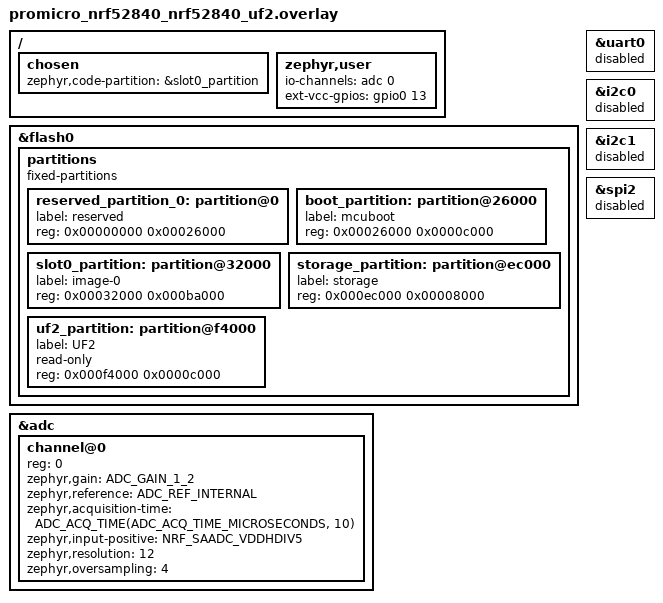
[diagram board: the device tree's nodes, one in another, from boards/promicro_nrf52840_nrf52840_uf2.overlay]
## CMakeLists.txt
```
#
# Copyright (c) 2025 Nordic Semiconductor ASA
#
# SPDX-License-Identifier: LicenseRef-Nordic-5-Clause
#

cmake_minimum_required(VERSION 3.20.0)

find_package(Zephyr REQUIRED HINTS $ENV{ZEPHYR_BASE})
project(beacon)

target_sources(app PRIVATE
    src/main.c
    src/bmt_auth.c
    src/bmt_beacon.c
    src/bmt_battery.c
)
```

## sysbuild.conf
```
# [SECURITY] MCUboot — tuong duong Secure Boot V2 ben ESP32 Tag.
# Single-slot mode: MCUboot chi verify chu ky + boot slot0_partition, chua
# ho tro OTA qua BLE (update = re-flash UF2 toan bo qua Adafruit bootloader
# co san, xem boards/xiao_ble_nrf52840.overlay de biet ly do layout nay).
SB_CONFIG_BOOTLOADER_MCUBOOT=y
SB_CONFIG_MCUBOOT_MODE_SINGLE_APP=y
SB_CONFIG_BOOT_SIGNATURE_TYPE_ECDSA_P256=y
SB_CONFIG_BOOT_SIGNATURE_KEY_FILE="../../mcuboot_keys/bmt_tag_ecdsa_p256.pem"
```

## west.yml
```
# Freestanding Zephyr application manifest. Lets `west init -l .` set up
# a workspace that pulls in upstream Zephyr next to this app, without
# requiring the whole nRF Connect SDK.
manifest:
  self:
    path: apps/Beacon_ProMicroNrf52840
  remotes:
    - name: zephyrproject
      url-base: https://github.com/zephyrproject-rtos
  projects:
    - name: zephyr
      remote: zephyrproject
      revision: v4.0.0
      import:
        name-allowlist:
          - hal_nordic
          - mcuboot
          - cmsis
          - segger
          - tinycrypt
```

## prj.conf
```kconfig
CONFIG_BT=y
CONFIG_BT_DEVICE_NAME="Test beacon"

# =====================================================================
# [POWER] Disable USB + CONSOLE + LOG — the largest single saving (~0.7 mA)
# =====================================================================
#
# The board uses USB CDC-ACM as its console (no dedicated UART for debug),
# so just having CONFIG_CONSOLE=y drags in the full USB device stack and
# keeps it running forever: CONFIG_USB_DEVICE_STACK_NEXT + CONFIG_UDC_NRF.
# Because CONFIG_PM_DEVICE is not enabled, nothing suspends them -> current
# is drawn continuously EVEN AFTER the USB cable is unplugged.
#
# Measured on this board (running from battery, USB unplugged, DT-9205A on
# the 200 mA range):
#   Full firmware (with USB / log)         1.7 mA
#   Empty firmware (no USB / log / BLE)    1.0 mA   <- the 0.7 mA diff is USB
#   Empty firmware + P0.13 LOW             0.9 mA   <- hardware floor, nothing to do
#
# DEBUG NOTE: turning this off means NO COM port and NO log. When you need
# logs, build with debug.conf to bring them back (see README, Build).
#
# Trying just CONFIG_LOG=n does NOT help — it only stops printing; the USB
# stack still initialises and runs. You must disable the console for the
# USB stack to actually be dropped from the build.
# THIS is the right switch (one line, instead of picking off each symbol).
# See zephyr/boards/common/usb/Kconfig.cdc_acm_serial.defconfig — the whole
#     if BOARD_SERIAL_BACKEND_CDC_ACM
#         config SERIAL                          default y
#         config CONSOLE                         default y
#         config USB_DEVICE_STACK_NEXT           default y if !MCUBOOT
#         config CDC_ACM_SERIAL_INITIALIZE_AT_BOOT  default y if !MCUBOOT
# block hangs off this switch, so disabling it drops the whole cluster.
#
# (Tried the piecemeal CONFIG_CONSOLE / UART_CONSOLE / SERIAL / LOG=n approach
#  first — did NOT work: .config still had USB_DEVICE_STACK_NEXT=y and
#  UDC_NRF=y, plus the build failed with "'__device_dts_ord_106' undeclared"
#  because cdc_acm_serial.c was still being compiled while the usbd node was
#  disabled in devicetree.)
CONFIG_BOARD_SERIAL_BACKEND_CDC_ACM=n
CONFIG_LOG=n

# [POWER] Turn off the soft switch that feeds power to the external VCC pin
# (P0.13) — saves ~0.1 mA. Needs the GPIO driver. See src/main.c and the
# overlay for the schematic detail.
CONFIG_GPIO=y

# PSA Crypto (HMAC-SHA256) — needed by bmt_auth for epoch key rotation.
CONFIG_PSA_CRYPTO=y
CONFIG_PSA_WANT_ALG_HMAC=y
CONFIG_PSA_WANT_ALG_SHA_256=y
CONFIG_PSA_WANT_KEY_TYPE_HMAC=y

# [POWER] Drop the radio TX power from the default 0 dBm to -4 dBm (matches
# the XIAO variant).
CONFIG_BT_CTLR_TX_PWR_MINUS_4=y

# [POWER] Read battery via the internal VDDHDIV5 — see bmt_battery.c and
# the overlay.
CONFIG_ADC=y

# =====================================================================
# [POWER] KEY DIFFERENCE VS THE XIAO VARIANT — DC/DC regulator
# =====================================================================
#
# The nRF52840 has TWO separate DC/DC regulators for two power architectures:
#
#  - REG1 ("normal voltage"): used when VDD is fed by an external LDO that
#    has already stepped the rail down. This is the XIAO case (battery ->
#    BQ25101 -> LDO SGM2040 3.3 V). The XIAO board devicetree ships both
#    regulators enabled:
#         &reg0 { status = "okay"; };
#         &reg1 { regulator-initial-mode = <NRF5X_REG_MODE_DCDC>; };
#    plus the L3 10 uH inductor between DCC / DEC4.
#
#  - REG0 ("high voltage"): used when the battery wires directly into VDDH
#    — the ProMicro / nice!nano v2 architecture.
#
# The ProMicro board in Zephyr does NOT configure reg0 / reg1 at all, so both
# stay at their defaults (REG1 in LDO mode, not DCDC).
#
# NOTE: the two legacy Kconfig symbols (CONFIG_SOC_DCDC_NRF52X / _HV) are
# DEPRECATED in this Zephyr version — DCDC must be enabled through
# DEVICETREE as shown above, not through prj.conf. (The
# CONFIG_BOARD_ENABLE_DCDC_HV symbol some ZMK guides mention is a ZMK-only
# thing and does not exist in upstream Zephyr.)
#
# NOT enabled in the initial version — DELIBERATE:
#   1) Cannot confirm this clone board has the inductor DCDC needs.
#   2) Real-world data from the ZMK community (issue zmkfirmware/zmk#2990)
#      shows enabling DC/DC HV mode on this class of board can INCREASE
#      current:
#         - Official nice!nano: +0.12-0.48 mA standby (up 20-25%)
#         - Clone boards: +1.30-1.32 mA (!!)
#      Suspicion: clones drop the inductor, so the switcher misbehaves
#      and draws more than the LDO would.
#
# => PLAN: measure current at the default first, then try enabling DCDC via
#    devicetree and remeasure. Only keep it if the numbers actually improve.

# =====================================================================
# [POWER] [TODO — not done, deliberate] Turn off unused peripherals
# =====================================================================
# The ProMicro board enables more peripherals than XIAO: i2c0, i2c1, pwm0,
# spi2, uart0 (see promicro_nrf52840_nrf52840_common.dts). This beacon app
# uses none of them, so disabling in principle would save a bit more.
#
# NOT done in the initial version: first want a WORKING image plus baseline
# current measurement, then disable one at a time AND remeasure to confirm
# each step. (Lesson from the XIAO variant: disabling SPI2 was thought to
# have hung the board, wasted hours debugging — the real culprit was
# flashing an unsigned app image. Since then, verify one config change at
# a time; don't change many things at once.)
#
# WATCH OUT: pwm0 is referenced by the "pwmleds" node (red_pwm_led);
# disabling pwm0 without handling that node will break the build.
```

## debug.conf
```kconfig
# =====================================================================
# DEBUG BUILD — re-enable console / log over USB CDC-ACM
# =====================================================================
#
# prj.conf (production) DISABLES USB + console + log because they draw
# ~0.7 mA continuously even after the USB cable is unplugged — see the
# full explanation in prj.conf.
#
# This file re-enables them so you can read logs for debugging. DO NOT
# USE FOR CURRENT MEASUREMENT: the reading will be ~0.7 mA higher than
# the real firmware.
#
# Build command:
#   west build -b promicro_nrf52840/nrf52840/uf2 -d build_debug . --pristine \
#       -- "-DBeacon_ProMicroNrf52840_EXTRA_CONF_FILE=debug.conf"
#
# (The "Beacon_ProMicroNrf52840_" prefix is required — this is a
#  sysbuild multi-image build; without the prefix CMake configure will
#  fail.)

# Re-enable the switch that prj.conf turned off. This drags in the
# whole cluster: SERIAL, CONSOLE, UART_CONSOLE, USB_DEVICE_STACK_NEXT,
# CDC_ACM_SERIAL_INITIALIZE_AT_BOOT (see prj.conf for the detail).
#
# NOTE: setting only CONFIG_CONSOLE=y / SERIAL=y without this line is
# USELESS — the console comes up but there is no UART device to send
# output to, so no COM port appears. (Been caught by this once.)
CONFIG_BOARD_SERIAL_BACKEND_CDC_ACM=y
CONFIG_LOG=y

# Bump the USB buffer pool to avoid "udc: Failed to allocate net_buf N"
# when USB control transactions and CDC-ACM log traffic overlap (after
# SUSPEND / RESUME).
CONFIG_UDC_BUF_POOL_SIZE=4096
CONFIG_UDC_BUF_COUNT=32
```

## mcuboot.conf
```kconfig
# [SECURITY] MCUboot tren XIAO nRF52840 dung USB CDC-ACM lam console mac dinh
# (board khong co UART debug rieng), nhung MCUboot KHONG bat USB stack (bootloader
# toi gian, khong can). Ket qua: console driver bi thieu link -> "undefined
# reference to __device_dts_ord_N". MCUboot khong can in log gi ca (chi verify
# chu ky + nhay sang slot0_partition) nen tat han console la cach don gian nhat,
# dong thoi giam attack surface (khong lo thong tin version/debug qua serial).
CONFIG_UART_CONSOLE=n
CONFIG_CONSOLE=n
```

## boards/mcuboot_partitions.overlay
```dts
/*
 * [SECURITY] Partition copy of promicro_nrf52840_nrf52840_uf2.overlay,
 * dedicated to MCUboot's own build (not the "beacon" app).
 *
 * WHY A SEPARATE FILE: Zephyr auto-applies boards/<board>.overlay only
 * to the main app. MCUboot is a COMPLETELY SEPARATE Zephyr app that
 * sysbuild builds in its own directory, so the overlay must be passed
 * explicitly via mcuboot_EXTRA_DTC_OVERLAY_FILE (see
 * sysbuild/CMakeLists.txt).
 *
 * DO NOT share a file with the app: "chosen { zephyr,code-partition }"
 * must DIFFER between the two — MCUboot must link into boot_partition
 * (0x26000) while the app must link into slot0_partition (0x32000).
 * Sharing would make MCUboot link into slot0 and overwrite the app
 * itself.
 *
 * (Note the 0x26000 base — DIFFERENT from XIAO at 0x27000. See the
 * full explanation in promicro_nrf52840_nrf52840_uf2.overlay.)
 *
 * This file ONLY declares partitions; no ADC / zephyr,user node —
 * MCUboot does not read the battery, adding one would only bloat the
 * bootloader.
 */

/delete-node/ &reserved_partition_0;
/delete-node/ &code_partition;
/delete-node/ &storage_partition;
/delete-node/ &boot_partition;

/ {
	chosen {
		zephyr,code-partition = &boot_partition;
	};
};

&flash0 {
	partitions {
		compatible = "fixed-partitions";
		#address-cells = <1>;
		#size-cells = <1>;

		reserved_partition_0: partition@0 {
			label = "reserved";
			reg = <0x00000000 0x00026000>;
		};

		boot_partition: partition@26000 {
			label = "mcuboot";
			reg = <0x00026000 0x0000c000>;
		};

		slot0_partition: partition@32000 {
			label = "image-0";
			reg = <0x00032000 0x000ba000>;
		};

		storage_partition: partition@ec000 {
			label = "storage";
			reg = <0x000ec000 0x00008000>;
		};

		uf2_partition: partition@f4000 {
			label = "UF2";
			read-only;
			reg = <0x000f4000 0x0000c000>;
		};
	};
};
```

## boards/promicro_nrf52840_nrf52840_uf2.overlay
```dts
/*
 * [SECURITY + POWER] MCUboot partition layout + battery-read setup —
 * Tag ProMicro nRF52840 (nice!nano v2-compatible, e.g. "Nologo
 * ProMicro nRF52840").
 *
 * ===== KEY DIFFERENCES VS THE XIAO VARIANT =====
 *
 * 1) DIFFERENT APP BASE ADDRESS (0x26000 vs 0x27000):
 *    ProMicro uses the Adafruit UF2 bootloader built for SoftDevice
 *    s140 *v6* (zephyr: nrf52840_partition_uf2_sdv6.dtsi), so the
 *    bootloader jumps to 0x26000. XIAO uses s140 *v7* -> jumps to
 *    0x27000. Put MCUboot at the wrong address and the board never
 *    boots the app.
 *
 * 2) BATTERY READ WITHOUT AN EXTERNAL DIVIDER:
 *    XIAO: battery -> BQ25101 -> external LDO; read via a 1M/510k
 *    divider brought out to P0.31 (AIN7), P0.14 must be driven LOW
 *    to close the measurement path.
 *    ProMicro / nice!nano v2: battery wires DIRECTLY into VDDH, no
 *    external divider — read the voltage via the SAADC's internal
 *    VDDHDIV5 input (= VDDH / 5). No enable pin required, and none
 *    of the Seeed over-voltage warnings for P0.14 apply.
 *
 * Layout (similar to XIAO but shifted down by 0x1000):
 *   0x00000 - 0x26000  reserved         (old SoftDevice region, unused)
 *   0x26000 - 0x32000  boot_partition   (MCUboot, 48 KB)
 *   0x32000 - 0xEC000  slot0_partition  (app, ~744 KB — single-slot)
 *   0xEC000 - 0xF4000  storage_partition (32 KB)
 *   0xF4000 - 0x100000 uf2_partition    (Adafruit bootloader — UNTOUCHED)
 */

/delete-node/ &reserved_partition_0;
/delete-node/ &code_partition;
/delete-node/ &storage_partition;
/delete-node/ &boot_partition;

/ {
	chosen {
		zephyr,code-partition = &slot0_partition;
	};

	/* [POWER] Battery read via the internal VDDHDIV5 (VDDH / 5) —
	 * see the top of file. No external io-channel to declare.
	 *
	 * [POWER] ext-vcc-gpios = SOFT SWITCH that gates the external
	 * VCC pin (P0.13). This board (standard nice!nano v2) has a
	 * MOSFET between the regulator and the external 3.3 V VCC pin,
	 * controlled by P0.13:
	 *     P0.13 HIGH -> VCC ON  |  P0.13 LOW -> VCC OFF
	 * (nice!nano v1 was inverted — v2 and this clone are
	 * active-high.)
	 *
	 * The Zephyr promicro_nrf52840 board definition does NOT
	 * declare this pin, so it stays in the reset state
	 * (input / disconnected) -> the switch defaults to "on" -> the
	 * external VCC rail is always powered, even when the app uses
	 * nothing. Per the SuperMini board's own datasheet, default
	 * standby is ~1000 uA (1 mA); turning this switch off brings
	 * it down to ~150 uA.
	 *
	 * => Matches what we saw: current measured 1.8-1.9 mA and
	 *    would NOT budge no matter what we changed (log off, USB
	 *    buffer resized, uart0 / i2c0 / i2c1 / spi2 disabled) —
	 *    because the leak was on external hardware, not something
	 *    firmware could touch.
	 *
	 * The beacon app powers no external device -> shut it off
	 * completely to save current.
	 */
	zephyr,user {
		io-channels = <&adc 0>;
		ext-vcc-gpios = <&gpio0 13 GPIO_ACTIVE_HIGH>;
	};
};

&flash0 {
	partitions {
		compatible = "fixed-partitions";
		#address-cells = <1>;
		#size-cells = <1>;

		reserved_partition_0: partition@0 {
			label = "reserved";
			reg = <0x00000000 0x00026000>;
		};

		boot_partition: partition@26000 {
			label = "mcuboot";
			reg = <0x00026000 0x0000c000>;
		};

		slot0_partition: partition@32000 {
			label = "image-0";
			reg = <0x00032000 0x000ba000>;
		};

		storage_partition: partition@ec000 {
			label = "storage";
			reg = <0x000ec000 0x00008000>;
		};

		uf2_partition: partition@f4000 {
			label = "UF2";
			read-only;
			reg = <0x000f4000 0x0000c000>;
		};
	};
};

/* [POWER] USB NOTE — do NOT disable here; disable via Kconfig.
 *
 * The board includes <boards/common/usb/cdc_acm_serial.dtsi>, which
 * creates board_cdc_acm_uart under &zephyr_udc0 and points chosen
 * zephyr,console at it. The USB stack draws ~0.8 mA continuously
 * (nearly half of the total), so it must be dropped in the production
 * build — but drop it with **CONFIG_BOARD_SERIAL_BACKEND_CDC_ACM=n**
 * in prj.conf, NOT by disabling the usbd node here.
 *
 * Reason: overlays under boards/ apply to EVERY build. Disabling the
 * usbd node here would break the debug.conf build (re-enables console
 * to read logs) — CONFIG_CONSOLE=y with no UART device to output to
 * leaves you with no COM port. Been caught by this before. Controlling
 * it through Kconfig lets each build enable / disable independently.
 */

/* [POWER TEST] Disable uart0 / i2c0 / i2c1 / spi2 — the board enables
 * these four peripherals with real pinctrl assignments, but the app
 * never touches them, so they may be FLOATING. Suspected as the
 * source of the stubborn ~1.9 mA that would not drop even after
 * disabling logs and resizing the USB buffer.
 * >> ACTUAL MEASUREMENT: no meaningful change (1.9 -> 1.8 mA, within
 *    meter noise). So this is NOT the culprit. Kept the change anyway
 *    because disabling unused peripherals is the right thing to do
 *    and causes no harm.
 * The console still runs over its own USB CDC-ACM path
 * (zephyr_udc0), independent of this physical uart0, so no logs are
 * lost. pwm0 is left alone because it is used by "red_pwm_led" (a
 * status LED). */
&uart0 {
	status = "disabled";
};

&i2c0 {
	status = "disabled";
};

&i2c1 {
	status = "disabled";
};

&spi2 {
	status = "disabled";
};

&adc {
	#address-cells = <1>;
	#size-cells = <0>;
	status = "okay";

	/* Channel 0 maps to the SAADC's internal VDDHDIV5 = VDDH / 5
	 * (no GPIO — the LiPo cell wires straight into VDDH on this
	 * board).
	 *
	 * Gain 1/2 + internal 0.6 V reference -> ADC input range =
	 * 0.6 * 2 = 1.2 V. A LiPo cell at 3.0-4.2 V gives VDDHDIV5
	 * 0.60-0.84 V: fits comfortably in the range with good
	 * resolution (~70% of full-scale at a full cell). Under USB,
	 * VDDH may climb to ~5.5 V -> 1.1 V, still under 1.2 V so no
	 * saturation. (Gain 1/6, as XIAO uses, would waste ~3/4 of
	 * the range here.)
	 *
	 * The source is a low-impedance internal divider, so it does
	 * NOT need the 40 us acquisition time the XIAO variant uses
	 * (which must compensate for the ~342k of the external
	 * divider). The default 10 us is plenty. */
	channel@0 {
		reg = <0>;
		zephyr,gain = "ADC_GAIN_1_2";
		zephyr,reference = "ADC_REF_INTERNAL";
		zephyr,acquisition-time = <ADC_ACQ_TIME(ADC_ACQ_TIME_MICROSECONDS, 10)>;
		zephyr,input-positive = <NRF_SAADC_VDDHDIV5>;
		zephyr,resolution = <12>;
		zephyr,oversampling = <4>;
	};
};
```

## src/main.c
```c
#include <zephyr/kernel.h>
#include <zephyr/sys/printk.h>
#include <zephyr/logging/log.h>

#include <zephyr/bluetooth/bluetooth.h>
#include <zephyr/drivers/gpio.h>

#include "bmt_auth.h"
#include "bmt_beacon.h"
#include "bmt_battery.h"

LOG_MODULE_REGISTER(bmt_main, LOG_LEVEL_INF);

/* [POWER] Soft switch that cuts power to the external VCC pin
 * (P0.13) — full explanation in
 * boards/promicro_nrf52840_nrf52840_uf2.overlay.
 * Summary: the 3.3 V branch routed to the external pin is powered
 * by default (Zephyr does not declare a control pin, so it stays
 * in its reset state), wasting ~1 mA even when the app powers
 * nothing external. */
static const struct gpio_dt_spec ext_vcc =
    GPIO_DT_SPEC_GET(DT_PATH(zephyr_user), ext_vcc_gpios);

static void ext_vcc_off(void)
{
	if (!gpio_is_ready_dt(&ext_vcc))
	{
		LOG_ERR("ext-vcc GPIO not ready");
		return;
	}

	/* INACTIVE + active-high = drive LOW = MOSFET off.
	 * Safe for the MCU: this MOSFET only sits on the external VCC
	 * rail; the nRF52840 itself is powered separately via VDDH. */
	int err = gpio_pin_configure_dt(&ext_vcc, GPIO_OUTPUT_INACTIVE);
	if (err)
	{
		LOG_ERR("Failed to turn off external VCC (err %d)", err);
		return;
	}
	LOG_INF("External VCC pin (P0.13) turned off");
}

static void bt_ready(int err)
{
	if (err)
	{
		LOG_ERR("Bluetooth init failed (err %d)", err);
		return;
	}
	LOG_INF("Bluetooth initialized");

	/* MUST be called before bmt_beacon_start() — the beacon needs
	 * the HMAC key ready so it can compute mac16 for the very
	 * first ADV. */
	bmt_auth_init();

	err = bmt_beacon_start();
	if (err)
	{
		LOG_ERR("bmt_beacon_start failed (err %d)", err);
		return;
	}
	LOG_INF("BMT Tag beacon started");
}

int main(void)
{
	printk("=== BMT Tag (nRF52840) starting ===\n");

	/* As EARLY as possible — every millisecond of delay lets current
	 * waste on the external VCC rail. */
	ext_vcc_off();

	/* Battery reading has nothing to do with BLE, start it in
	 * parallel with bt_enable. */
	int batt_err = bmt_battery_init();
	if (batt_err)
	{
		LOG_ERR("bmt_battery_init failed (err %d)", batt_err);
	}

	int err = bt_enable(bt_ready);
	if (err)
	{
		LOG_ERR("bt_enable failed (err %d)", err);
	}
	return 0;
}
```

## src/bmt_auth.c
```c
#include "bmt_auth.h"

#include <inttypes.h>

#include <zephyr/kernel.h>
#include <zephyr/logging/log.h>
#include "psa/crypto.h"

LOG_MODULE_REGISTER(bmt_auth, LOG_LEVEL_INF);

/* [SECURITY] Master key — NOT used directly to sign the payload. It
 * derives a separate key per epoch (rotated over time, TOTP-style,
 * receiver-less: Tag has no mesh / WiFi, so it cannot receive a
 * pushed rotation like the OTA-beacon key does on Scanner). If this
 * key is stolen from flash, the attacker still has to recompute the
 * current epoch key — they cannot "replay a single static key
 * forever".
 * MUST match BMT_TAG_MASTER_KEY on the ESP32 Tag byte-for-byte. */
static const uint8_t BMT_TAG_MASTER_KEY[16] = {
    0x2C, 0x5C, 0xBE, 0x42, 0x87, 0xAE, 0x95, 0x4A,
    0xDE, 0xEE, 0x0C, 0x6C, 0x8B, 0x74, 0x9C, 0x45};

/* Epoch tick = 1 h. Tag has no RTC / WiFi, so the epoch is a LOCAL
 * counter measured from boot (k_uptime_get(), not wall-clock) —
 * resets to 0 on every power loss (CR2032 swap). Scanner deals with
 * the drift via windowed resync. MUST match the value on the
 * Scanner (ESP32). */
#define BMT_EPOCH_TICK_SEC 3600

static psa_key_id_t s_master_key_id = 0;
static psa_key_id_t s_epoch_key_id = 0;
static uint16_t s_cached_epoch = 0xFFFF; /* invalid value -> forces derivation on first use */

static uint16_t current_epoch(void)
{
	/* k_uptime_get() returns milliseconds (int64_t) since boot —
	 * different from ESP-IDF's esp_timer_get_time() which is
	 * microseconds. Adjust the scale factor accordingly. */
	return (uint16_t)(k_uptime_get() / (1000LL * BMT_EPOCH_TICK_SEC));
}

static void ensure_epoch_key(uint16_t epoch)
{
	if (epoch == s_cached_epoch && s_epoch_key_id != 0)
		return;

	uint8_t derived[32];
	size_t derived_len = 0;
	uint8_t epoch_le[2] = {(uint8_t)(epoch & 0xFF), (uint8_t)(epoch >> 8)};

	psa_status_t st = psa_mac_compute(s_master_key_id, PSA_ALG_HMAC(PSA_ALG_SHA_256),
	                                  epoch_le, sizeof(epoch_le), derived, sizeof(derived), &derived_len);
	if (st != PSA_SUCCESS)
	{
		LOG_ERR("derive epoch key failed: %d", (int)st);
		return;
	}

	if (s_epoch_key_id != 0)
		psa_destroy_key(s_epoch_key_id);

	psa_key_attributes_t attr = PSA_KEY_ATTRIBUTES_INIT;
	psa_set_key_usage_flags(&attr, PSA_KEY_USAGE_SIGN_MESSAGE);
	psa_set_key_algorithm(&attr, PSA_ALG_HMAC(PSA_ALG_SHA_256));
	psa_set_key_type(&attr, PSA_KEY_TYPE_HMAC);
	psa_set_key_bits(&attr, 128);

	st = psa_import_key(&attr, derived, 16, &s_epoch_key_id);
	if (st != PSA_SUCCESS)
	{
		LOG_ERR("import epoch key failed: %d", (int)st);
		s_epoch_key_id = 0;
		return;
	}
	s_cached_epoch = epoch;
	LOG_INF("[SECURITY] epoch key rotated -> epoch=%u", epoch);
}

void bmt_auth_init(void)
{
	psa_status_t st = psa_crypto_init();
	if (st != PSA_SUCCESS)
	{
		LOG_ERR("psa_crypto_init failed: %d", (int)st);
		return;
	}

	psa_key_attributes_t attr = PSA_KEY_ATTRIBUTES_INIT;
	psa_set_key_usage_flags(&attr, PSA_KEY_USAGE_SIGN_MESSAGE);
	psa_set_key_algorithm(&attr, PSA_ALG_HMAC(PSA_ALG_SHA_256));
	psa_set_key_type(&attr, PSA_KEY_TYPE_HMAC);
	psa_set_key_bits(&attr, 8 * sizeof(BMT_TAG_MASTER_KEY));

	st = psa_import_key(&attr, BMT_TAG_MASTER_KEY, sizeof(BMT_TAG_MASTER_KEY), &s_master_key_id);
	if (st != PSA_SUCCESS)
	{
		LOG_ERR("psa_import_key failed: %d", (int)st);
		return;
	}
	ensure_epoch_key(current_epoch());
	LOG_INF("HMAC master key imported OK (key_id=%" PRIu32 ")", (uint32_t)s_master_key_id);
}

uint16_t bmt_auth_hmac16(const uint8_t* data, size_t len)
{
	ensure_epoch_key(current_epoch());

	uint8_t mac[32];
	size_t mac_len = 0;

	psa_status_t st = psa_mac_compute(s_epoch_key_id, PSA_ALG_HMAC(PSA_ALG_SHA_256),
	                                  data, len, mac, sizeof(mac), &mac_len);
	if (st != PSA_SUCCESS)
	{
		LOG_ERR("psa_mac_compute failed: %d", (int)st);
		return 0;
	}
	return (uint16_t)((mac[0] << 8) | mac[1]);
}
```

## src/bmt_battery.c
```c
#include "bmt_battery.h"

#include <zephyr/kernel.h>
#include <zephyr/device.h>
#include <zephyr/devicetree.h>
#include <zephyr/drivers/adc.h>
#include <zephyr/logging/log.h>

LOG_MODULE_REGISTER(bmt_battery, LOG_LEVEL_INF);

/* Battery wires directly into nRF52840's VDDH (nice!nano v2
 * high-voltage mode). Read via the SAADC's internal VDDHDIV5 —
 * no external divider and no GPIO enable needed (unlike XIAO,
 * which needs P0.31 + P0.14). */
static const struct adc_dt_spec battery_adc = ADC_DT_SPEC_GET_BY_IDX(DT_PATH(zephyr_user), 0);

/* VDDHDIV5: raw reading = VDDH / 5, so multiply by 5 to recover the
 * actual battery voltage. Replaces the (R1+R2)/R2 external-divider
 * ratio used on XIAO. */
#define BMT_BATT_VDDH_DIVIDER 5

/* Voltage -> percent lookup for Li-ion / LiPo. The Li-ion SoC-vs-
 * voltage curve is strongly non-linear, so a single linear formula
 * would be wrong across the range — use a table and interpolate
 * between adjacent points. 4200 mV = 100% (full), 3300 mV = 0%
 * (safe lower cutoff; below this the cell degrades). Identical to
 * the XIAO variant — same battery chemistry, same curve. */
typedef struct
{
	uint16_t mv;
	uint8_t pct;
} batt_point_t;

static const batt_point_t BATT_CURVE[] = {
    {4200, 100},
    {4110, 90},
    {4020, 80},
    {3930, 70},
    {3840, 60},
    {3750, 50},
    {3660, 40},
    {3570, 30},
    {3480, 20},
    {3390, 10},
    {3300, 0},
};
#define BATT_CURVE_N (sizeof(BATT_CURVE) / sizeof(BATT_CURVE[0]))

#define BMT_BATT_LOG_INTERVAL_SEC 30

static struct k_timer batt_log_timer;
static struct k_work batt_log_work;

/* Cached % — the beacon reads this and embeds it in each ADV
 * (instead of hitting the ADC per packet). Refreshed by the work
 * handler (30 s) and once synchronously during init. */
static uint8_t s_last_percent = 0;

uint8_t bmt_battery_last_percent(void)
{
	return s_last_percent;
}

int bmt_battery_read_mv(void)
{
	int16_t raw = 0;
	struct adc_sequence sequence = {
	    .buffer = &raw,
	    .buffer_size = sizeof(raw),
	};

	int err = adc_sequence_init_dt(&battery_adc, &sequence);
	if (err < 0)
	{
		LOG_ERR("adc_sequence_init_dt failed (%d)", err);
		return err;
	}

	err = adc_read_dt(&battery_adc, &sequence);
	if (err < 0)
	{
		LOG_ERR("adc_read_dt failed (%d)", err);
		return err;
	}

	int32_t adc_mv = raw;
	err = adc_raw_to_millivolts_dt(&battery_adc, &adc_mv);
	if (err < 0)
	{
		LOG_ERR("adc_raw_to_millivolts_dt failed (%d)", err);
		return err;
	}

	/* Multiply by the VDDHDIV5 ratio to recover the real VDDH voltage. */
	return adc_mv * BMT_BATT_VDDH_DIVIDER;
}

uint8_t bmt_battery_percent(int mv)
{
	if (mv >= BATT_CURVE[0].mv)
		return 100;
	if (mv <= BATT_CURVE[BATT_CURVE_N - 1].mv)
		return 0;

	for (size_t i = 0; i < BATT_CURVE_N - 1; i++)
	{
		uint16_t hi = BATT_CURVE[i].mv;
		uint16_t lo = BATT_CURVE[i + 1].mv;
		if (mv <= hi && mv >= lo)
		{
			/* Linear interpolation between the two adjacent points. */
			int pct_hi = BATT_CURVE[i].pct;
			int pct_lo = BATT_CURVE[i + 1].pct;
			return (uint8_t)(pct_lo + ((mv - lo) * (pct_hi - pct_lo)) / (hi - lo));
		}
	}
	return 0;
}

bool bmt_battery_is_charging(void)
{
	/* This board does NOT route the charger IC's ~CHG pin to any
	 * readable GPIO — unlike XIAO (P0.17). Return false to keep the
	 * API parity with the XIAO variant.
	 *
	 * Could be inferred indirectly from VDDH itself: when USB is
	 * connected, VDDH climbs to ~5 V, well above a full battery
	 * (4.2 V). Not implemented — need a real board to calibrate
	 * the threshold first. */
	return false;
}

static void batt_log_work_handler(struct k_work* work)
{
	ARG_UNUSED(work);

	int mv = bmt_battery_read_mv();
	if (mv < 0)
	{
		LOG_ERR("Battery read failed (%d)", mv);
		return;
	}
	s_last_percent = bmt_battery_percent(mv);
	LOG_INF("[BATTERY] VDDH=%d mV (~%u%%)", mv, s_last_percent);
}

static void batt_log_timer_handler(struct k_timer* timer)
{
	/* k_timer callback runs in ISR context; adc_read may block,
	 * so hand it off to the workqueue. */
	ARG_UNUSED(timer);
	k_work_submit(&batt_log_work);
}

int bmt_battery_init(void)
{
	if (!adc_is_ready_dt(&battery_adc))
	{
		LOG_ERR("ADC device %s not ready", battery_adc.dev->name);
		return -ENODEV;
	}

	int err = adc_channel_setup_dt(&battery_adc);
	if (err < 0)
	{
		LOG_ERR("adc_channel_setup_dt failed (%d)", err);
		return err;
	}

	LOG_INF("Battery ADC (internal VDDHDIV5) ready");

	/* Synchronous read once so s_last_percent has a valid value
	 * BEFORE the beacon starts advertising (build_adv_data reads
	 * bmt_battery_last_percent). */
	int mv0 = bmt_battery_read_mv();
	if (mv0 >= 0)
		s_last_percent = bmt_battery_percent(mv0);

	k_work_init(&batt_log_work, batt_log_work_handler);
	k_timer_init(&batt_log_timer, batt_log_timer_handler, NULL);
	k_timer_start(&batt_log_timer, K_SECONDS(BMT_BATT_LOG_INTERVAL_SEC),
	              K_SECONDS(BMT_BATT_LOG_INTERVAL_SEC));

	/* Print once at boot as well. */
	k_work_submit(&batt_log_work);

	return 0;
}
```

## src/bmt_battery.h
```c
#pragma once

#include <stdbool.h>
#include <stdint.h>

/* Initialise the battery ADC. On ProMicro / nice!nano v2 the battery
 * wires directly into the VDDH pin, read via the SAADC's internal
 * VDDHDIV5 input — no external divider, no GPIO enable needed (very
 * different from XIAO). See bmt_battery.c. */
int bmt_battery_init(void);

/* Read the actual battery voltage at VDDH (compensating for the /5
 * ratio of VDDHDIV5), in mV. Returns < 0 on error. */
int bmt_battery_read_mv(void);

/* Estimate remaining battery percentage from voltage using a Li-ion
 * lookup curve (interpolated, see BATT_CURVE in bmt_battery.c). 0-100. */
uint8_t bmt_battery_percent(int mv);

/* This board does not expose a charging-status GPIO, so this always
 * returns false. Kept for API parity with the XIAO variant (bmt_beacon
 * shares the same headers). */
bool bmt_battery_is_charging(void);

/* Cached % from the most recent periodic read — used by the beacon
 * to embed in each ADV payload without re-reading the ADC. Refreshed
 * by a 30 s timer in bmt_battery.c and once synchronously at init. */
uint8_t bmt_battery_last_percent(void);
```

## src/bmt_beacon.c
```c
#include "bmt_beacon.h"

#include <string.h>

#include <zephyr/kernel.h>
#include <zephyr/random/random.h>
#include <zephyr/logging/log.h>

#include <zephyr/bluetooth/bluetooth.h>
#include <zephyr/bluetooth/hci.h>

#include "bmt_config.h"
#include "bmt_auth.h"
#include "bmt_types.h"
#include "bmt_battery.h"

LOG_MODULE_REGISTER(bmt_beacon, LOG_LEVEL_INF);

/* Espressif Company ID (0x02E5) — kept so existing Scanners (ESP32)
 * still recognise the tag, even though the Tag now runs a Nordic
 * chip. Scanner filters by this CID in the manufacturer data; the
 * actual chip vendor is unrelated. */
#define BMT_CID_ESPRESSIF 0x02E5

static uint8_t s_sequence = 0;
static bool s_adv_active = false;

/* Manufacturer-data buffer = 2 B CID (little-endian) + 24 B payload.
 * Backed by a static buffer (not stack) because bt_le_adv_start()
 * needs a valid data pointer at call time — same approach as
 * s_adv_raw on ESP32. */
static uint8_t s_mfg_data[2 + sizeof(bmt_tag_adv_payload_t)];

static struct k_timer s_seq_timer;
static struct k_work s_seq_work;

static void build_adv_data(void)
{
	bmt_tag_adv_payload_t p;

	memcpy(p.uuid, BMT_SYSTEM_UUID, 16);
	/* This field used to be major (PERSON / ASSET); now carries
	 * battery % (0-100). Reads the cached value (bmt_battery
	 * refreshes it every 30 s) instead of hitting the ADC on every
	 * ADV — lighter on the battery. */
	p.battery = bmt_battery_last_percent();
	p.minor = BMT_TAG_MINOR;
	p.tx_power = BMT_TAG_TX_POWER;
	p.sequence = s_sequence;
	p.mac16 = 0; /* must be 0 before computing HMAC */

	/* HMAC covers every field except the last 2 mac16 bytes —
	 * exactly the same formula as ESP32, only the API call differs
	 * (bmt_auth_hmac16 is shared naming). */
	p.mac16 = bmt_auth_hmac16((uint8_t*)&p, sizeof(p) - sizeof(p.mac16));

	s_mfg_data[0] = (uint8_t)(BMT_CID_ESPRESSIF & 0xFF);
	s_mfg_data[1] = (uint8_t)(BMT_CID_ESPRESSIF >> 8);
	memcpy(s_mfg_data + 2, &p, sizeof(p));
}

static void start_adv_random_interval(void)
{
	/* Random [900, 1100] ms -> avoid collision with other tags,
	 * same range as ESP32. */
	uint32_t ms = BMT_ADV_INTERVAL_MIN_MS +
	              (sys_rand32_get() % (BMT_ADV_INTERVAL_MAX_MS - BMT_ADV_INTERVAL_MIN_MS + 1));

	/* One-shot: timer fires exactly after "ms" ms — in sync with
	 * the radio interval currently in use (900-1100 ms). A fixed
	 * 500 ms auto-reload timer would sit in the middle of a radio
	 * cycle and adv_stop / start incorrectly, doubling the average
	 * transmit rate. */
	k_timer_start(&s_seq_timer, K_MSEC(ms), K_NO_WAIT);

	/* BLE unit = 0.625 ms — same unit as ESP-IDF, formula identical. */
	uint16_t units = (uint16_t)((ms * 1000) / 625);

	build_adv_data();

	const struct bt_le_adv_param param = {
	    .id = BT_ID_DEFAULT,
	    .sid = 0,
	    .secondary_max_skip = 0,
	    .options = BT_LE_ADV_OPT_USE_IDENTITY, /* public address, not private / random-rotating */
	    .interval_min = units,
	    .interval_max = units,
	    .peer = NULL,
	};

	const struct bt_data ad[] = {
	    /* Flags = 0x06 (LE General Discoverable | No BR/EDR) — same
	     * hardcoded value as ESP32. */
	    BT_DATA_BYTES(BT_DATA_FLAGS, (BT_LE_AD_GENERAL | BT_LE_AD_NO_BREDR)),
	    BT_DATA(BT_DATA_MANUFACTURER_DATA, s_mfg_data, sizeof(s_mfg_data)),
	};

	int err = bt_le_adv_start(&param, ad, ARRAY_SIZE(ad), NULL, 0);
	if (err)
	{
		LOG_ERR("ADV start FAILED (err %d)", err);
		s_adv_active = false;
		return;
	}
	s_adv_active = true;
	LOG_DBG("ADV OK seq=%u batt=%u%% minor=0x%04X", s_sequence,
	        bmt_battery_last_percent(), BMT_TAG_MINOR);
}

static void seq_work_handler(struct k_work* work)
{
	ARG_UNUSED(work);
	s_sequence++; /* uint8_t: 255 -> 0 automatically, same as ESP32 */

	bt_le_adv_stop();
	start_adv_random_interval();
}

static void seq_timer_handler(struct k_timer* timer)
{
	/* [IMPORTANT] k_timer callbacks run in ISR context — must NOT
	 * call bt_le_adv_stop / start here (they can block and would
	 * fault). Dispatch the real work to the system workqueue via
	 * k_work, same principle as "FreeRTOS timer callback stays
	 * short, heavy work goes to its own task", but Zephyr enforces
	 * this stricter than ESP32 does. */
	ARG_UNUSED(timer);
	k_work_submit(&s_seq_work);
}

int bmt_beacon_start(void)
{
	k_work_init(&s_seq_work, seq_work_handler);

	/* One-shot: interval is reset inside start_adv_random_interval(). */
	k_timer_init(&s_seq_timer, seq_timer_handler, NULL);

	/* First advertise — this function calls k_timer_start() itself. */
	start_adv_random_interval();

	return 0;
}

uint8_t bmt_beacon_sequence(void)
{
	return s_sequence;
}

bool bmt_beacon_is_active(void)
{
	return s_adv_active;
}

uint16_t bmt_beacon_last_mac16(void)
{
	bmt_tag_adv_payload_t p;
	memcpy(&p, s_mfg_data + 2, sizeof(p));
	return p.mac16;
}
```

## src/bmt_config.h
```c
#pragma once

#include <stdint.h>

/* System UUID — IDENTICAL across all tags (ESP32 + nRF52840 + iPhone).
 * Scanner checks the first 4 bytes (AB 00 00 00) to recognise
 * "our system's tag". */
static const uint8_t BMT_SYSTEM_UUID[16] = {
    0xAB, 0x00, 0x00, 0x00, 0x00, 0x00, 0x00, 0x00,
    0x00, 0x00, 0x00, 0x00, 0x00, 0x00, 0x00, 0x00};
#define BMT_TAG_MINOR 0x0001   /* tag ID — change per device */
#define BMT_TAG_TX_POWER (-53) /* calibrate: measure RSSI at 1 m, then set */
/* (BMT_TAG_MAJOR PERSON/ASSET removed — the payload now uses those 2 bytes for battery %.) */

/* [POWER] Random ADV interval range — avoids collisions with other
 * tags. Raised from 450-550 ms to ~900-1100 ms to reduce battery
 * drain: the radio transmits about half as often, so average current
 * drops and battery/diode sag is smaller. Scanner updates positions
 * about twice as slowly (~1 s), acceptable for a worn tag. Lower
 * again for faster localisation at the cost of battery. */
#define BMT_ADV_INTERVAL_MIN_MS 900
#define BMT_ADV_INTERVAL_MAX_MS 1100

/* [TODO power-opt] Actual radio TX power (distinct from BMT_TAG_TX_POWER
 * above, which is the "declared" value in the payload the Scanner uses
 * for distance estimation). On Zephyr / nRF52 this is set via Kconfig
 * (CONFIG_BT_CTLR_TX_PWR_*), not a runtime API like ESP-IDF. Will be
 * addressed in the power-optimisation pass. */
```

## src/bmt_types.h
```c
#pragma once

#include <stdint.h>

/* MUST match the ESP32 struct byte-for-byte
 * (apps/tag/components/bmt_beacon/bmt_beacon.h). This is the only
 * interface between Tag and the rest of the system (Scanner / Mesh /
 * Gateway). A single-byte drift makes the Scanner refuse to recognise
 * the tag. */
#pragma pack(1)
typedef struct
{
	uint8_t uuid[16];    /* 16B: system UUID (AB000000-...) */
	uint16_t battery;    /*  2B: remaining battery % (0-100). Was "major"
	                      *      (PERSON/ASSET) — dropped because worn
	                      *      tags don't need the classification.
	                      *      Position and size kept, so HMAC and the
	                      *      24 B layout are unchanged. */
	uint16_t minor;      /*  2B: tag ID within the system */
	int8_t tx_power;     /*  1B: measured power at 1 m (calibrated) */
	uint8_t sequence;    /*  1B: 0-255, wraps -> Scanner computes loss rate */
	uint16_t mac16;      /*  2B: truncated HMAC-SHA256 (replaces CRC16) */
} bmt_tag_adv_payload_t; /* = 24 bytes */
#pragma pack()
```
